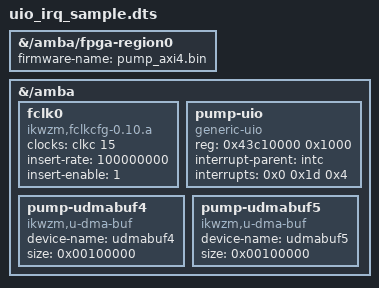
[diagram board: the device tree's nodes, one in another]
/dts-v1/;/plugin/;
/ {
	fragment@0 {
		target-path = "/amba/fpga-region0";
		__overlay__ {
			firmware-name = "pump_axi4.bin";
		};
	};
	fragment@1 {
		target-path = "/amba";
		#address-cells = <0x1>;
		#size-cells = <0x1>;
		__overlay__ {
			#address-cells = <0x1>;
			#size-cells = <0x1>;
			fclk0 {
				compatible    = "ikwzm,fclkcfg-0.10.a";
				clocks        = <&clkc 15>;
				insert-rate   = "100000000";
				insert-enable = <1>;
			};
			pump-uio {
				compatible = "generic-uio";
				reg = <0x43c10000 0x1000>;
				interrupt-parent = <&intc>;
				interrupts = <0x0 0x1d 0x4>;
	                };

			pump-udmabuf4 {
				compatible  = "ikwzm,u-dma-buf";
				device-name = "udmabuf4";
				size = <0x00100000>;
	                };

			pump-udmabuf5 {
				compatible = "ikwzm,u-dma-buf";
				device-name = "udmabuf5";
				size = <0x00100000>;
			};
                };
	};
};
